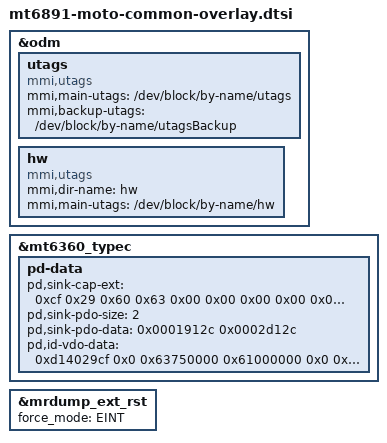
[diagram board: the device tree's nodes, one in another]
/* Copyright (c) 2020, The Linux Foundation. All rights reserved.
 *
 * This program is free software; you can redistribute it and/or modify
 * it under the terms of the GNU General Public License version 2 and
 * only version 2 as published by the Free Software Foundation.
 *
 * This program is distributed in the hope that it will be useful,
 * but WITHOUT ANY WARRANTY; without even the implied warranty of
 * MERCHANTABILITY or FITNESS FOR A PARTICULAR PURPOSE.  See the
 * GNU General Public License for more details.
 */
/dts-v1/;
/plugin/;
#include <dt-bindings/interrupt-controller/irq.h>
#include <dt-bindings/interrupt-controller/arm-gic.h>
#include <dt-bindings/spmi/spmi.h>
#include <dt-bindings/pinctrl/mt6885-pinfunc.h>
#include "mediatek/carrier-channel-ids.dtsi"

&odm {
    utags {
        compatible = "mmi,utags";
        mmi,main-utags = "/dev/block/by-name/utags";
        mmi,backup-utags = "/dev/block/by-name/utagsBackup";
    };
    hw {
        compatible = "mmi,utags";
        mmi,dir-name = "hw";
        mmi,main-utags = "/dev/block/by-name/hw";
    };
};
&mt6360_typec {
	pd-data {
            pd,sink-cap-ext = /bits/ 8 <0xcf 0x29 0x60 0x63
                                            0x00 0x00 0x00 0x00
                                            0x00 0x00 0x01 0x00
                                            0x00 0x00 0x00 0x00
                                            0x01 0x0b 0x01 0x0a
                                            0x1b 0x00 0x00 0x00>;
            /*5V, 3A  9V, 3A*/
            pd,sink-pdo-size = <2>;
            pd,sink-pdo-data = <0x0001912c 0x0002d12c> ;
            pd,id-vdo-data = <0xd14029cf 0x0 0x63750000
                            0x61000000 0x0 0x41000000>;
	};
};
/* disable manual mrdump start */
&mrdump_ext_rst {
    force_mode = "EINT";
};
/* disable manual mrdump end */

